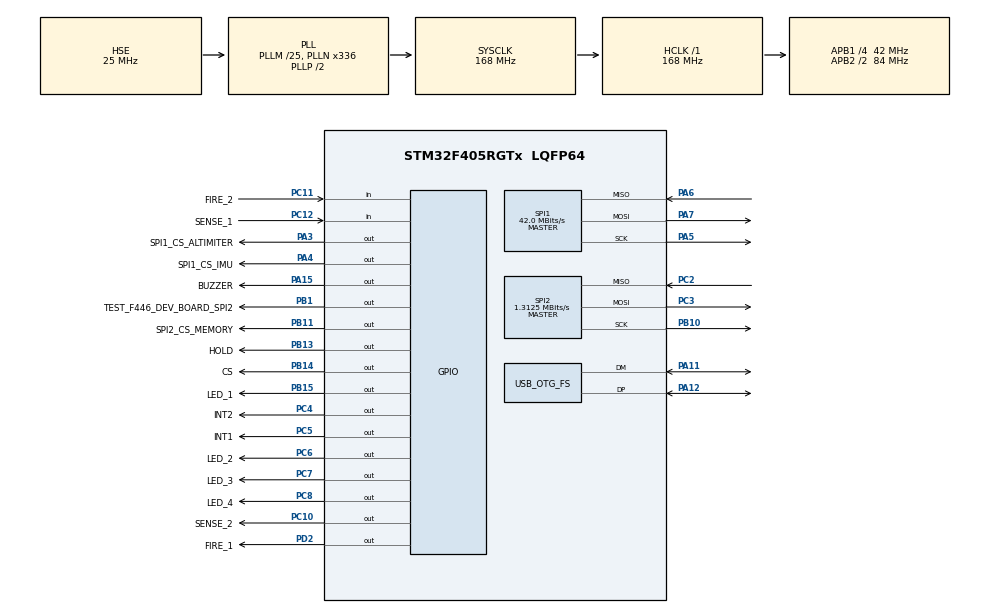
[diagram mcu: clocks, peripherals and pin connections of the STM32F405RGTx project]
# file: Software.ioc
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FREERTOS.Tasks01=defaultTask,24,128,StartDefaultTask,Default,NULL,Dynamic,NULL,NULL
Mcu.Family=STM32F4
Mcu.Name=STM32F405RGTx
Mcu.Package=LQFP64
NVIC.OTG_FS_IRQn=true\:5\:0\:false\:false\:true\:true\:false\:true\:true
NVIC.PriorityGroup=NVIC_PRIORITYGROUP_4
NVIC.SPI2_IRQn=true\:5\:0\:false\:false\:true\:true\:true\:true\:true
NVIC.TIM6_DAC_IRQn=true\:15\:0\:false\:false\:true\:false\:false\:true\:true
NVIC.TimeBase=TIM6_DAC_IRQn
NVIC.TimeBaseIP=TIM6
PA11.Mode=Device_Only
PA11.Signal=USB_OTG_FS_DM
PA12.Mode=Device_Only
PA12.Signal=USB_OTG_FS_DP
PA13.Mode=Serial_Wire
PA13.Signal=SYS_JTMS-SWDIO
PA14.Mode=Serial_Wire
PA14.Signal=SYS_JTCK-SWCLK
PA15.GPIO_Label=BUZZER
PA15.Signal=GPIO_Output
PA3.GPIO_Label=SPI1_CS_ALTIMITER
PA3.Signal=GPIO_Output
PA4.GPIO_Label=SPI1_CS_IMU
PA4.Signal=GPIO_Output
PA5.Mode=Full_Duplex_Master
PA5.Signal=SPI1_SCK
PA6.Mode=Full_Duplex_Master
PA6.Signal=SPI1_MISO
PA7.Mode=Full_Duplex_Master
PA7.Signal=SPI1_MOSI
PB1.GPIO_Label=TEST_F446_DEV_BOARD_SPI2
PB1.Signal=GPIO_Output
PB10.Mode=Full_Duplex_Master
PB10.Signal=SPI2_SCK
PB11.GPIO_Label=SPI2_CS_MEMORY
PB11.Signal=GPIO_Output
PB13.GPIO_Label=HOLD
PB13.Signal=GPIO_Output
PB14.GPIO_Label=CS
PB14.Signal=GPIO_Output
PB15.GPIO_Label=LED_1
PB15.Signal=GPIO_Output
PB3.Signal=SYS_JTDO-SWO
PC10.GPIO_Label=SENSE_2
PC10.Signal=GPIO_Output
PC11.GPIO_Label=FIRE_2
PC11.Signal=GPIO_Input
PC12.GPIO_Label=SENSE_1
PC12.Signal=GPIO_Input
PC2.Mode=Full_Duplex_Master
PC2.Signal=SPI2_MISO
PC3.Mode=Full_Duplex_Master
PC3.Signal=SPI2_MOSI
PC4.GPIO_Label=INT2
PC4.Signal=GPIO_Output
PC5.GPIO_Label=INT1
PC5.Signal=GPIO_Output
PC6.GPIO_Label=LED_2
PC6.Signal=GPIO_Output
PC7.GPIO_Label=LED_3
PC7.Signal=GPIO_Output
PC8.GPIO_Label=LED_4
PC8.Signal=GPIO_Output
PD2.GPIO_Label=FIRE_1
PD2.Signal=GPIO_Output
PH0-OSC_IN.Mode=HSE-External-Oscillator
PH0-OSC_IN.Signal=RCC_OSC_IN
PH1-OSC_OUT.Mode=HSE-External-Oscillator
PH1-OSC_OUT.Signal=RCC_OSC_OUT
ProjectManager.HeapSize=0x200
ProjectManager.StackSize=0x400
ProjectManager.TargetToolchain=STM32CubeIDE
RCC.48MHZClocksFreq_Value=48000000
RCC.AHBFreq_Value=168000000
RCC.APB1CLKDivider=RCC_HCLK_DIV4
RCC.APB1Freq_Value=42000000
RCC.APB1TimFreq_Value=84000000
RCC.APB2CLKDivider=RCC_HCLK_DIV2
RCC.APB2Freq_Value=84000000
RCC.APB2TimFreq_Value=168000000
RCC.CortexFreq_Value=168000000
RCC.HCLKFreq_Value=168000000
RCC.HSE_VALUE=25000000
RCC.HSI_VALUE=16000000
RCC.LSE_VALUE=32768
RCC.PLLM=25
RCC.PLLN=336
RCC.PLLQ=7
RCC.SYSCLKFreq_VALUE=168000000
RCC.SYSCLKSource=RCC_SYSCLKSOURCE_PLLCLK
RCC.VCOOutputFreq_Value=336000000
SPI1.BaudRatePrescaler=SPI_BAUDRATEPRESCALER_2
SPI1.CalculateBaudRate=42.0 MBits/s
SPI1.Direction=SPI_DIRECTION_2LINES
SPI1.Mode=SPI_MODE_MASTER
SPI1.VirtualType=VM_MASTER
SPI2.BaudRatePrescaler=SPI_BAUDRATEPRESCALER_32
SPI2.CalculateBaudRate=1.3125 MBits/s
SPI2.Direction=SPI_DIRECTION_2LINES
SPI2.Mode=SPI_MODE_MASTER
SPI2.VirtualType=VM_MASTER
USB_DEVICE.CLASS_NAME_FS=CDC
USB_DEVICE.VirtualMode-CDC_FS=Cdc
USB_DEVICE.VirtualModeFS=Cdc_FS
USB_OTG_FS.VirtualMode=Device_Only
VP_FREERTOS_VS_CMSIS_V2.Mode=CMSIS_V2
VP_RTC_VS_RTC_Activate.Mode=RTC_Enabled
VP_SYS_VS_tim6.Mode=TIM6
VP_USB_DEVICE_VS_USB_DEVICE_CDC_FS.Mode=CDC_FS
board=custom

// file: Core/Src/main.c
/* USER CODE BEGIN Header */
/**
  ******************************************************************************
  * @file           : main.c
  * @brief          : Main program body
  ******************************************************************************
  * @attention
  *
  * Copyright (c) 2022 STMicroelectronics.
  * All rights reserved.
  *
  * This software is licensed under terms that can be found in the LICENSE file
  * in the root directory of this software component.
  * If no LICENSE file comes with this software, it is provided AS-IS.
  *
  ******************************************************************************
  */
/* USER CODE END Header */
#include "main.h"
#include "cmsis_os.h"
#include "usb_device.h"

/* USER CODE BEGIN Includes */
#include "app_barometer.h"
#include "app_buzzer.h"
#include "app_heartbeat.h"
#include "app_imu.h"
#include "app_main.h"
#include "app_memory.h"
#include "app_usb.h"
/* USER CODE END Includes */

 RTC_HandleTypeDef hrtc;

SPI_HandleTypeDef hspi1;
SPI_HandleTypeDef hspi2;

/* Definitions for defaultTask */
osThreadId_t defaultTaskHandle;
const osThreadAttr_t defaultTask_attributes = {
  .name = "defaultTask",
  .stack_size = 128 * 4,
  .priority = (osPriority_t) osPriorityNormal,
};

void SystemClock_Config(void);
static void MX_GPIO_Init(void);
static void MX_SPI1_Init(void);
static void MX_SPI2_Init(void);
static void MX_RTC_Init(void);
void StartDefaultTask(void *argument);

int main(void)
{

  /* MCU Configuration--------------------------------------------------------*/

  /* Reset of all peripherals, Initializes the Flash interface and the Systick. */
  HAL_Init();

  /* Configure the system clock */
  SystemClock_Config();

  /* Initialize all configured peripherals */
  MX_GPIO_Init();
  MX_SPI1_Init();
  MX_SPI2_Init();
  MX_RTC_Init();

  /* Init scheduler */
  osKernelInitialize();

  /* Create the thread(s) */
  /* creation of defaultTask */
  defaultTaskHandle = osThreadNew(StartDefaultTask, NULL, &defaultTask_attributes);

  /* USER CODE BEGIN RTOS_THREADS */
  initBarometerTask(hspi1);
  initBuzzerTask();
  initHeartbeatTask();
  initIMUTask(hspi1);
  initMainTask();
  initMemoryTask(hspi2);
  initUSBTask();
  /* USER CODE END RTOS_THREADS */

  /* Start scheduler */
  osKernelStart();

  /* We should never get here as control is now taken by the scheduler */
  /* Infinite loop */
  while (1)
  {

  }
}

void SystemClock_Config(void)
{
  RCC_OscInitTypeDef RCC_OscInitStruct = {0};
  RCC_ClkInitTypeDef RCC_ClkInitStruct = {0};

  /** Configure the main internal regulator output voltage
  */
  __HAL_RCC_PWR_CLK_ENABLE();
  __HAL_PWR_VOLTAGESCALING_CONFIG(PWR_REGULATOR_VOLTAGE_SCALE1);

  /** Initializes the RCC Oscillators according to the specified parameters
  * in the RCC_OscInitTypeDef structure.
  */
  RCC_OscInitStruct.OscillatorType = RCC_OSCILLATORTYPE_LSI|RCC_OSCILLATORTYPE_HSE;
  RCC_OscInitStruct.HSEState = RCC_HSE_ON;
  RCC_OscInitStruct.LSIState = RCC_LSI_ON;
  RCC_OscInitStruct.PLL.PLLState = RCC_PLL_ON;
  RCC_OscInitStruct.PLL.PLLSource = RCC_PLLSOURCE_HSE;
  RCC_OscInitStruct.PLL.PLLM = 25;
  RCC_OscInitStruct.PLL.PLLN = 336;
  RCC_OscInitStruct.PLL.PLLP = RCC_PLLP_DIV2;
  RCC_OscInitStruct.PLL.PLLQ = 7;
  if (HAL_RCC_OscConfig(&RCC_OscInitStruct) != HAL_OK)
  {
    Error_Handler();
  }

  /** Initializes the CPU, AHB and APB buses clocks
  */
  RCC_ClkInitStruct.ClockType = RCC_CLOCKTYPE_HCLK|RCC_CLOCKTYPE_SYSCLK
                              |RCC_CLOCKTYPE_PCLK1|RCC_CLOCKTYPE_PCLK2;
  RCC_ClkInitStruct.SYSCLKSource = RCC_SYSCLKSOURCE_PLLCLK;
  RCC_ClkInitStruct.AHBCLKDivider = RCC_SYSCLK_DIV1;
  RCC_ClkInitStruct.APB1CLKDivider = RCC_HCLK_DIV4;
  RCC_ClkInitStruct.APB2CLKDivider = RCC_HCLK_DIV2;

  if (HAL_RCC_ClockConfig(&RCC_ClkInitStruct, FLASH_LATENCY_5) != HAL_OK)
  {
    Error_Handler();
  }
}

static void MX_RTC_Init(void)
{

  /** Initialize RTC Only
  */
  hrtc.Instance = RTC;
  hrtc.Init.HourFormat = RTC_HOURFORMAT_24;
  hrtc.Init.AsynchPrediv = 127;
  hrtc.Init.SynchPrediv = 255;
  hrtc.Init.OutPut = RTC_OUTPUT_DISABLE;
  hrtc.Init.OutPutPolarity = RTC_OUTPUT_POLARITY_HIGH;
  hrtc.Init.OutPutType = RTC_OUTPUT_TYPE_OPENDRAIN;
  if (HAL_RTC_Init(&hrtc) != HAL_OK)
  {
    Error_Handler();
  }

}

static void MX_SPI1_Init(void)
{

  /* SPI1 parameter configuration*/
  hspi1.Instance = SPI1;
  hspi1.Init.Mode = SPI_MODE_MASTER;
  hspi1.Init.Direction = SPI_DIRECTION_2LINES;
  hspi1.Init.DataSize = SPI_DATASIZE_8BIT;
  hspi1.Init.CLKPolarity = SPI_POLARITY_LOW;
  hspi1.Init.CLKPhase = SPI_PHASE_1EDGE;
  hspi1.Init.NSS = SPI_NSS_SOFT;
  hspi1.Init.BaudRatePrescaler = SPI_BAUDRATEPRESCALER_2;
  hspi1.Init.FirstBit = SPI_FIRSTBIT_MSB;
  hspi1.Init.TIMode = SPI_TIMODE_DISABLE;
  hspi1.Init.CRCCalculation = SPI_CRCCALCULATION_DISABLE;
  hspi1.Init.CRCPolynomial = 10;
  if (HAL_SPI_Init(&hspi1) != HAL_OK)
  {
    Error_Handler();
  }

}

static void MX_SPI2_Init(void)
{

  /* SPI2 parameter configuration*/
  hspi2.Instance = SPI2;
  hspi2.Init.Mode = SPI_MODE_MASTER;
  hspi2.Init.Direction = SPI_DIRECTION_2LINES;
  hspi2.Init.DataSize = SPI_DATASIZE_8BIT;
  hspi2.Init.CLKPolarity = SPI_POLARITY_LOW;
  hspi2.Init.CLKPhase = SPI_PHASE_1EDGE;
  hspi2.Init.NSS = SPI_NSS_SOFT;
  hspi2.Init.BaudRatePrescaler = SPI_BAUDRATEPRESCALER_32;
  hspi2.Init.FirstBit = SPI_FIRSTBIT_MSB;
  hspi2.Init.TIMode = SPI_TIMODE_DISABLE;
  hspi2.Init.CRCCalculation = SPI_CRCCALCULATION_DISABLE;
  hspi2.Init.CRCPolynomial = 10;
  if (HAL_SPI_Init(&hspi2) != HAL_OK)
  {
    Error_Handler();
  }

}

static void MX_GPIO_Init(void)
{
  GPIO_InitTypeDef GPIO_InitStruct = {0};

  /* GPIO Ports Clock Enable */
  __HAL_RCC_GPIOH_CLK_ENABLE();
  __HAL_RCC_GPIOC_CLK_ENABLE();
  __HAL_RCC_GPIOA_CLK_ENABLE();
  __HAL_RCC_GPIOB_CLK_ENABLE();
  __HAL_RCC_GPIOD_CLK_ENABLE();

  /*Configure GPIO pin Output Level */
  HAL_GPIO_WritePin(GPIOA, SPI1_CS_ALTIMITER_Pin|SPI1_CS_IMU_Pin|BUZZER_Pin, GPIO_PIN_RESET);

  /*Configure GPIO pin Output Level */
  HAL_GPIO_WritePin(GPIOC, INT2_Pin|INT1_Pin|LED_2_Pin|LED_3_Pin
                          |LED_4_Pin|SENSE_2_Pin, GPIO_PIN_RESET);

  /*Configure GPIO pin Output Level */
  HAL_GPIO_WritePin(GPIOB, TEST_F446_DEV_BOARD_SPI2_Pin|SPI2_CS_MEMORY_Pin|HOLD_Pin|CS_Pin
                          |LED_1_Pin, GPIO_PIN_RESET);

  /*Configure GPIO pin Output Level */
  HAL_GPIO_WritePin(FIRE_1_GPIO_Port, FIRE_1_Pin, GPIO_PIN_RESET);

  /*Configure GPIO pins : SPI1_CS_ALTIMITER_Pin SPI1_CS_IMU_Pin BUZZER_Pin */
  GPIO_InitStruct.Pin = SPI1_CS_ALTIMITER_Pin|SPI1_CS_IMU_Pin|BUZZER_Pin;
  GPIO_InitStruct.Mode = GPIO_MODE_OUTPUT_PP;
  GPIO_InitStruct.Pull = GPIO_NOPULL;
  GPIO_InitStruct.Speed = GPIO_SPEED_FREQ_LOW;
  HAL_GPIO_Init(GPIOA, &GPIO_InitStruct);

  /*Configure GPIO pins : INT2_Pin INT1_Pin LED_2_Pin LED_3_Pin
                           LED_4_Pin SENSE_2_Pin */
  GPIO_InitStruct.Pin = INT2_Pin|INT1_Pin|LED_2_Pin|LED_3_Pin
                          |LED_4_Pin|SENSE_2_Pin;
  GPIO_InitStruct.Mode = GPIO_MODE_OUTPUT_PP;
  GPIO_InitStruct.Pull = GPIO_NOPULL;
  GPIO_InitStruct.Speed = GPIO_SPEED_FREQ_LOW;
  HAL_GPIO_Init(GPIOC, &GPIO_InitStruct);

  /*Configure GPIO pins : TEST_F446_DEV_BOARD_SPI2_Pin SPI2_CS_MEMORY_Pin HOLD_Pin CS_Pin
                           LED_1_Pin */
  GPIO_InitStruct.Pin = TEST_F446_DEV_BOARD_SPI2_Pin|SPI2_CS_MEMORY_Pin|HOLD_Pin|CS_Pin
                          |LED_1_Pin;
  GPIO_InitStruct.Mode = GPIO_MODE_OUTPUT_PP;
  GPIO_InitStruct.Pull = GPIO_NOPULL;
  GPIO_InitStruct.Speed = GPIO_SPEED_FREQ_LOW;
  HAL_GPIO_Init(GPIOB, &GPIO_InitStruct);

  /*Configure GPIO pins : FIRE_2_Pin SENSE_1_Pin */
  GPIO_InitStruct.Pin = FIRE_2_Pin|SENSE_1_Pin;
  GPIO_InitStruct.Mode = GPIO_MODE_INPUT;
  GPIO_InitStruct.Pull = GPIO_NOPULL;
  HAL_GPIO_Init(GPIOC, &GPIO_InitStruct);

  /*Configure GPIO pin : FIRE_1_Pin */
  GPIO_InitStruct.Pin = FIRE_1_Pin;
  GPIO_InitStruct.Mode = GPIO_MODE_OUTPUT_PP;
  GPIO_InitStruct.Pull = GPIO_NOPULL;
  GPIO_InitStruct.Speed = GPIO_SPEED_FREQ_LOW;
  HAL_GPIO_Init(FIRE_1_GPIO_Port, &GPIO_InitStruct);

}

void StartDefaultTask(void *argument)
{
  /* init code for USB_DEVICE */
  MX_USB_DEVICE_Init();
  for(;;)
  {
    osDelay(1);
  }
}

void HAL_TIM_PeriodElapsedCallback(TIM_HandleTypeDef *htim)
{
  if (htim->Instance == TIM6) {
    HAL_IncTick();
  }
}

void Error_Handler(void)
{
  __disable_irq();
  while (1)
  {
  }
}
